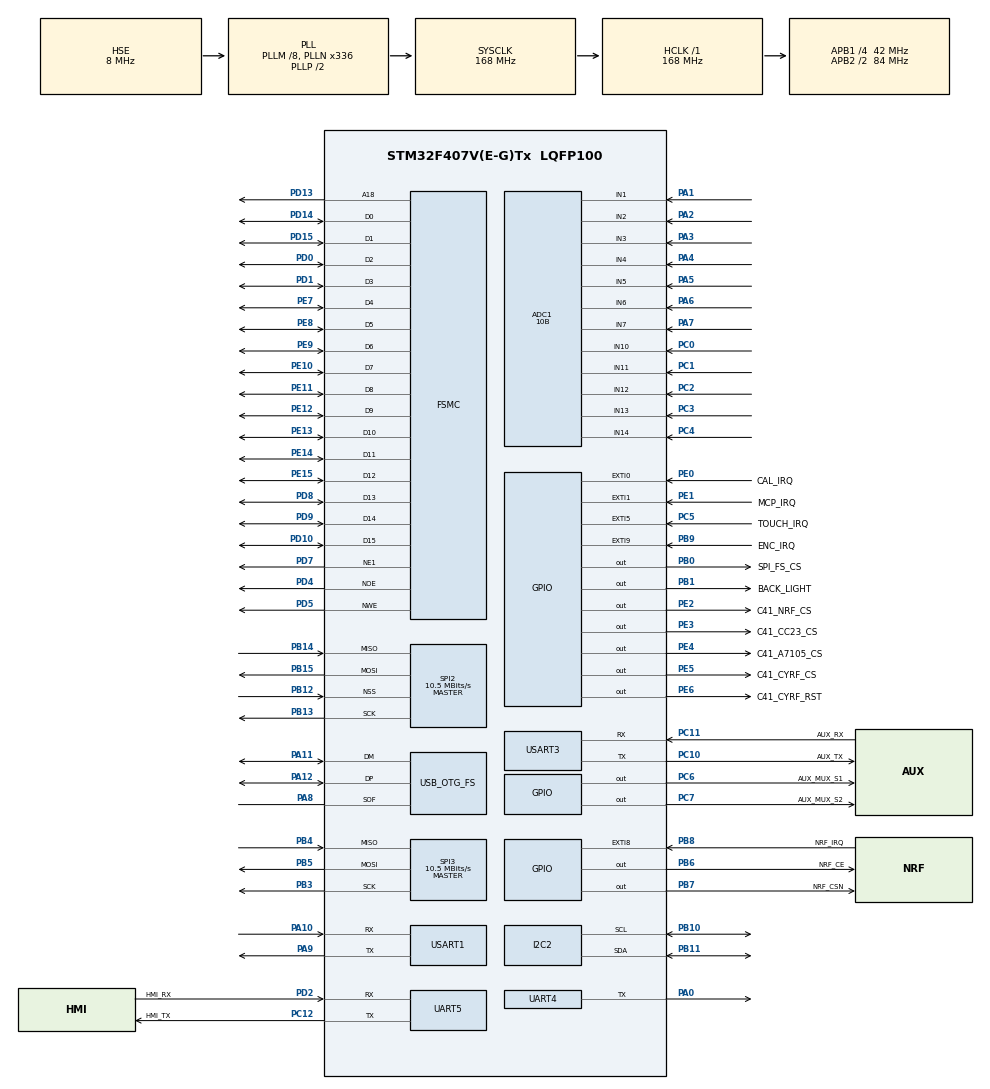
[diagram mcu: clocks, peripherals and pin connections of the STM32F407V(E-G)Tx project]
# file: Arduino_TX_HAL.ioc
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ADC1.Channel-10\#ChannelRegularConversion=ADC_CHANNEL_11
ADC1.Channel-11\#ChannelRegularConversion=ADC_CHANNEL_12
ADC1.Channel-12\#ChannelRegularConversion=ADC_CHANNEL_13
ADC1.Channel-13\#ChannelRegularConversion=ADC_CHANNEL_14
ADC1.Channel-2\#ChannelRegularConversion=ADC_CHANNEL_1
ADC1.Channel-3\#ChannelRegularConversion=ADC_CHANNEL_2
ADC1.Channel-4\#ChannelRegularConversion=ADC_CHANNEL_3
ADC1.Channel-5\#ChannelRegularConversion=ADC_CHANNEL_4
ADC1.Channel-6\#ChannelRegularConversion=ADC_CHANNEL_5
ADC1.Channel-7\#ChannelRegularConversion=ADC_CHANNEL_6
ADC1.Channel-8\#ChannelRegularConversion=ADC_CHANNEL_7
ADC1.Channel-9\#ChannelRegularConversion=ADC_CHANNEL_10
ADC1.ClockPrescaler=ADC_CLOCK_SYNC_PCLK_DIV4
ADC1.ContinuousConvMode=ENABLE
ADC1.DMAContinuousRequests=ENABLE
ADC1.EOCSelection=ADC_EOC_SEQ_CONV
ADC1.NbrOfConversion=12
ADC1.NbrOfConversionFlag=1
ADC1.Rank-10\#ChannelRegularConversion=9
ADC1.Rank-11\#ChannelRegularConversion=10
ADC1.Rank-12\#ChannelRegularConversion=11
ADC1.Rank-13\#ChannelRegularConversion=12
ADC1.Rank-2\#ChannelRegularConversion=1
ADC1.Rank-3\#ChannelRegularConversion=2
ADC1.Rank-4\#ChannelRegularConversion=3
ADC1.Rank-5\#ChannelRegularConversion=4
ADC1.Rank-6\#ChannelRegularConversion=5
ADC1.Rank-7\#ChannelRegularConversion=6
ADC1.Rank-8\#ChannelRegularConversion=7
ADC1.Rank-9\#ChannelRegularConversion=8
ADC1.Resolution=ADC_RESOLUTION_10B
ADC1.SamplingTime-10\#ChannelRegularConversion=ADC_SAMPLETIME_144CYCLES
ADC1.SamplingTime-11\#ChannelRegularConversion=ADC_SAMPLETIME_144CYCLES
ADC1.SamplingTime-12\#ChannelRegularConversion=ADC_SAMPLETIME_144CYCLES
ADC1.SamplingTime-13\#ChannelRegularConversion=ADC_SAMPLETIME_144CYCLES
ADC1.SamplingTime-2\#ChannelRegularConversion=ADC_SAMPLETIME_144CYCLES
ADC1.SamplingTime-3\#ChannelRegularConversion=ADC_SAMPLETIME_144CYCLES
ADC1.SamplingTime-4\#ChannelRegularConversion=ADC_SAMPLETIME_144CYCLES
ADC1.SamplingTime-5\#ChannelRegularConversion=ADC_SAMPLETIME_144CYCLES
ADC1.SamplingTime-6\#ChannelRegularConversion=ADC_SAMPLETIME_144CYCLES
ADC1.SamplingTime-7\#ChannelRegularConversion=ADC_SAMPLETIME_144CYCLES
ADC1.SamplingTime-8\#ChannelRegularConversion=ADC_SAMPLETIME_144CYCLES
ADC1.SamplingTime-9\#ChannelRegularConversion=ADC_SAMPLETIME_144CYCLES
ADC1.ScanConvMode=ENABLE
ADC1.master=1
AL94.I-CUBE-USBD-COMPOSITE.1.0.3.CompositeCcUSBJjCOMPOSITEJjCDCIiACM=true
AL94.I-CUBE-USBD-COMPOSITE.1.0.3.CompositeCcUSBJjCOMPOSITEJjCOMPOSITE=true
AL94.I-CUBE-USBD-COMPOSITE.1.0.3.CompositeCcUSBJjCOMPOSITEJjCore=true
AL94.I-CUBE-USBD-COMPOSITE.1.0.3.CompositeCcUSBJjCOMPOSITEJjDFU=true
AL94.I-CUBE-USBD-COMPOSITE.1.0.3.CompositeCcUSBJjCOMPOSITEJjMSCIiBOT=true
AL94.I-CUBE-USBD-COMPOSITE.1.0.3._USBD_CDC_ACM_COUNT=2
AL94.I-CUBE-USBD-COMPOSITE.1.0.3._USBD_USE_CDC_ACM=true
AL94.I-CUBE-USBD-COMPOSITE.1.0.3._USBD_USE_DFU=true
AL94.I-CUBE-USBD-COMPOSITE.1.0.3._USBD_USE_MSC=true
Dma.ADC1.0.Direction=DMA_PERIPH_TO_MEMORY
Dma.ADC1.0.FIFOMode=DMA_FIFOMODE_DISABLE
Dma.ADC1.0.Instance=DMA2_Stream0
Dma.ADC1.0.MemDataAlignment=DMA_MDATAALIGN_HALFWORD
Dma.ADC1.0.MemInc=DMA_MINC_ENABLE
Dma.ADC1.0.Mode=DMA_CIRCULAR
Dma.ADC1.0.PeriphDataAlignment=DMA_PDATAALIGN_HALFWORD
Dma.ADC1.0.PeriphInc=DMA_PINC_DISABLE
Dma.ADC1.0.Priority=DMA_PRIORITY_LOW
Dma.Request0=ADC1
Dma.Request1=USART1_RX
Dma.Request2=USART1_TX
Dma.Request3=USART3_RX
Dma.Request4=USART3_TX
Dma.Request5=UART5_RX
Dma.Request6=UART5_TX
Dma.Request7=UART4_TX
Dma.UART4_TX.7.Direction=DMA_MEMORY_TO_PERIPH
Dma.UART4_TX.7.FIFOMode=DMA_FIFOMODE_DISABLE
Dma.UART4_TX.7.Instance=DMA1_Stream4
Dma.UART4_TX.7.MemDataAlignment=DMA_MDATAALIGN_BYTE
Dma.UART4_TX.7.MemInc=DMA_MINC_ENABLE
Dma.UART4_TX.7.Mode=DMA_NORMAL
Dma.UART4_TX.7.PeriphDataAlignment=DMA_PDATAALIGN_BYTE
Dma.UART4_TX.7.PeriphInc=DMA_PINC_DISABLE
Dma.UART4_TX.7.Priority=DMA_PRIORITY_LOW
Dma.UART5_RX.5.Direction=DMA_PERIPH_TO_MEMORY
Dma.UART5_RX.5.FIFOMode=DMA_FIFOMODE_DISABLE
Dma.UART5_RX.5.Instance=DMA1_Stream0
Dma.UART5_RX.5.MemDataAlignment=DMA_MDATAALIGN_BYTE
Dma.UART5_RX.5.MemInc=DMA_MINC_ENABLE
Dma.UART5_RX.5.Mode=DMA_NORMAL
Dma.UART5_RX.5.PeriphDataAlignment=DMA_PDATAALIGN_BYTE
Dma.UART5_RX.5.PeriphInc=DMA_PINC_DISABLE
Dma.UART5_RX.5.Priority=DMA_PRIORITY_LOW
Dma.UART5_TX.6.Direction=DMA_MEMORY_TO_PERIPH
Dma.UART5_TX.6.FIFOMode=DMA_FIFOMODE_DISABLE
Dma.UART5_TX.6.Instance=DMA1_Stream7
Dma.UART5_TX.6.MemDataAlignment=DMA_MDATAALIGN_BYTE
Dma.UART5_TX.6.MemInc=DMA_MINC_ENABLE
Dma.UART5_TX.6.Mode=DMA_NORMAL
Dma.UART5_TX.6.PeriphDataAlignment=DMA_PDATAALIGN_BYTE
Dma.UART5_TX.6.PeriphInc=DMA_PINC_DISABLE
Dma.UART5_TX.6.Priority=DMA_PRIORITY_LOW
Dma.USART1_RX.1.Direction=DMA_PERIPH_TO_MEMORY
Dma.USART1_RX.1.FIFOMode=DMA_FIFOMODE_DISABLE
Dma.USART1_RX.1.Instance=DMA2_Stream2
Dma.USART1_RX.1.MemDataAlignment=DMA_MDATAALIGN_BYTE
Dma.USART1_RX.1.MemInc=DMA_MINC_ENABLE
Dma.USART1_RX.1.Mode=DMA_CIRCULAR
Dma.USART1_RX.1.PeriphDataAlignment=DMA_PDATAALIGN_BYTE
Dma.USART1_RX.1.PeriphInc=DMA_PINC_DISABLE
Dma.USART1_RX.1.Priority=DMA_PRIORITY_HIGH
Dma.USART1_TX.2.Direction=DMA_MEMORY_TO_PERIPH
Dma.USART1_TX.2.FIFOMode=DMA_FIFOMODE_DISABLE
Dma.USART1_TX.2.Instance=DMA2_Stream7
Dma.USART1_TX.2.MemDataAlignment=DMA_MDATAALIGN_BYTE
Dma.USART1_TX.2.MemInc=DMA_MINC_ENABLE
Dma.USART1_TX.2.Mode=DMA_NORMAL
Dma.USART1_TX.2.PeriphDataAlignment=DMA_PDATAALIGN_BYTE
Dma.USART1_TX.2.PeriphInc=DMA_PINC_DISABLE
Dma.USART1_TX.2.Priority=DMA_PRIORITY_MEDIUM
Dma.USART3_RX.3.Direction=DMA_PERIPH_TO_MEMORY
Dma.USART3_RX.3.FIFOMode=DMA_FIFOMODE_DISABLE
Dma.USART3_RX.3.Instance=DMA1_Stream1
Dma.USART3_RX.3.MemDataAlignment=DMA_MDATAALIGN_BYTE
Dma.USART3_RX.3.MemInc=DMA_MINC_ENABLE
Dma.USART3_RX.3.Mode=DMA_NORMAL
Dma.USART3_RX.3.PeriphDataAlignment=DMA_PDATAALIGN_BYTE
Dma.USART3_RX.3.PeriphInc=DMA_PINC_DISABLE
Dma.USART3_RX.3.Priority=DMA_PRIORITY_LOW
Dma.USART3_TX.4.Direction=DMA_MEMORY_TO_PERIPH
Dma.USART3_TX.4.FIFOMode=DMA_FIFOMODE_DISABLE
Dma.USART3_TX.4.Instance=DMA1_Stream3
Dma.USART3_TX.4.MemDataAlignment=DMA_MDATAALIGN_BYTE
Dma.USART3_TX.4.MemInc=DMA_MINC_ENABLE
Dma.USART3_TX.4.Mode=DMA_NORMAL
Dma.USART3_TX.4.PeriphDataAlignment=DMA_PDATAALIGN_BYTE
Dma.USART3_TX.4.PeriphInc=DMA_PINC_DISABLE
Dma.USART3_TX.4.Priority=DMA_PRIORITY_LOW
I2C2.I2C_Mode=I2C_Fast
Mcu.Family=STM32F4
Mcu.Name=STM32F407V(E-G)Tx
Mcu.Package=LQFP100
NVIC.ADC_IRQn=true\:5\:0\:true\:false\:true\:true\:true\:true
NVIC.DMA1_Stream0_IRQn=true\:7\:0\:true\:false\:true\:false\:true\:true
NVIC.DMA1_Stream1_IRQn=true\:7\:0\:true\:false\:true\:false\:true\:true
NVIC.DMA1_Stream3_IRQn=true\:7\:0\:true\:false\:true\:false\:true\:true
NVIC.DMA1_Stream4_IRQn=true\:7\:0\:true\:false\:true\:false\:true\:true
NVIC.DMA1_Stream7_IRQn=true\:7\:0\:true\:false\:true\:false\:true\:true
NVIC.DMA2_Stream0_IRQn=true\:7\:0\:true\:false\:true\:false\:true\:true
NVIC.DMA2_Stream2_IRQn=true\:7\:0\:true\:false\:true\:false\:true\:true
NVIC.DMA2_Stream7_IRQn=true\:5\:0\:true\:false\:true\:false\:true\:true
NVIC.EXTI0_IRQn=true\:5\:0\:true\:false\:true\:true\:true\:true
NVIC.EXTI1_IRQn=true\:5\:0\:true\:false\:true\:true\:true\:true
NVIC.EXTI9_5_IRQn=true\:5\:0\:true\:false\:true\:true\:true\:true
NVIC.OTG_FS_IRQn=true\:5\:0\:true\:false\:true\:true\:true\:true
NVIC.PriorityGroup=NVIC_PRIORITYGROUP_4
NVIC.TIM8_TRG_COM_TIM14_IRQn=true\:5\:0\:true\:false\:true\:false\:true\:true
NVIC.TimeBase=TIM8_TRG_COM_TIM14_IRQn
NVIC.TimeBaseIP=TIM14
NVIC.UART4_IRQn=true\:0\:0\:false\:false\:true\:true\:true\:true
NVIC.UART5_IRQn=true\:5\:0\:true\:false\:true\:true\:true\:true
NVIC.USART1_IRQn=true\:5\:0\:true\:false\:true\:true\:true\:true
NVIC.USART3_IRQn=true\:5\:0\:true\:false\:true\:true\:true\:true
PA0-WKUP.Mode=Half_duplex(single_wire_mode)
PA0-WKUP.Signal=UART4_TX
PA1.Signal=ADCx_IN1
PA10.Mode=Asynchronous
PA10.Signal=USART1_RX
PA11.Mode=Device_Only
PA11.Signal=USB_OTG_FS_DM
PA12.Mode=Device_Only
PA12.Signal=USB_OTG_FS_DP
PA13.Mode=Serial_Wire
PA13.Signal=SYS_JTMS-SWDIO
PA14.Mode=Serial_Wire
PA14.Signal=SYS_JTCK-SWCLK
PA2.Signal=ADCx_IN2
PA3.Signal=ADCx_IN3
PA4.Signal=ADCx_IN4
PA5.Signal=ADCx_IN5
PA6.Signal=ADCx_IN6
PA7.Signal=ADCx_IN7
PA8.Mode=Activate_SOF_FS
PA8.Signal=USB_OTG_FS_SOF
PA9.Mode=Asynchronous
PA9.Signal=USART1_TX
PB0.GPIO_Label=SPI_FS_CS
PB0.PinState=GPIO_PIN_SET
PB0.Signal=GPIO_Output
PB1.GPIO_Label=BACK_LIGHT
PB1.Signal=GPIO_Output
PB10.Mode=I2C
PB10.Signal=I2C2_SCL
PB11.Mode=I2C
PB11.Signal=I2C2_SDA
PB12.Mode=NSS_Signal_Hard_Input
PB12.Signal=SPI2_NSS
PB13.Mode=Full_Duplex_Master
PB13.Signal=SPI2_SCK
PB14.Mode=Full_Duplex_Master
PB14.Signal=SPI2_MISO
PB15.Mode=Full_Duplex_Master
PB15.Signal=SPI2_MOSI
PB3.Mode=Full_Duplex_Master
PB3.Signal=SPI3_SCK
PB4.Mode=Full_Duplex_Master
PB4.Signal=SPI3_MISO
PB5.Mode=Full_Duplex_Master
PB5.Signal=SPI3_MOSI
PB6.GPIO_Label=NRF_CE
PB6.GPIO_Speed=GPIO_SPEED_FREQ_VERY_HIGH
PB6.Signal=GPIO_Output
PB7.GPIO_Label=NRF_CSN
PB7.GPIO_Speed=GPIO_SPEED_FREQ_VERY_HIGH
PB7.PinState=GPIO_PIN_SET
PB7.Signal=GPIO_Output
PB8.GPIO_Label=NRF_IRQ
PB8.Signal=GPXTI8
PB9.GPIO_Label=ENC_IRQ
PB9.GPIO_ModeDefaultEXTI=GPIO_MODE_IT_FALLING
PB9.GPIO_PuPd=GPIO_PULLUP
PB9.Signal=GPXTI9
PC0.Signal=ADCx_IN10
PC1.Signal=ADCx_IN11
PC10.GPIO_Label=AUX_TX
PC10.Mode=Asynchronous
PC10.Signal=USART3_TX
PC11.GPIO_Label=AUX_RX
PC11.Mode=Asynchronous
PC11.Signal=USART3_RX
PC12.GPIO_Label=HMI_TX
PC12.Mode=Asynchronous
PC12.Signal=UART5_TX
PC14-OSC32_IN.Mode=LSE-External-Oscillator
PC14-OSC32_IN.Signal=RCC_OSC32_IN
PC15-OSC32_OUT.Mode=LSE-External-Oscillator
PC15-OSC32_OUT.Signal=RCC_OSC32_OUT
PC2.Signal=ADCx_IN12
PC3.Signal=ADCx_IN13
PC4.Signal=ADCx_IN14
PC5.GPIO_Label=TOUCH_IRQ
PC5.GPIO_ModeDefaultEXTI=GPIO_MODE_IT_FALLING
PC5.GPIO_PuPd=GPIO_PULLUP
PC5.Signal=GPXTI5
PC6.GPIO_Label=AUX_MUX_S1
PC6.Signal=GPIO_Output
PC7.GPIO_Label=AUX_MUX_S2
PC7.Signal=GPIO_Output
PD0.Mode=16b-d1
PD0.Signal=FSMC_D2
PD1.Mode=16b-d1
PD1.Signal=FSMC_D3
PD10.Mode=16b-d1
PD10.Signal=FSMC_D15
PD13.Mode=A18_1
PD13.Signal=FSMC_A18
PD14.Mode=16b-d1
PD14.Signal=FSMC_D0
PD15.Mode=16b-d1
PD15.Signal=FSMC_D1
PD2.GPIO_Label=HMI_RX
PD2.Mode=Asynchronous
PD2.Signal=UART5_RX
PD4.Mode=Lcd1
PD4.Signal=FSMC_NOE
PD5.Mode=Lcd1
PD5.Signal=FSMC_NWE
PD7.Mode=NorPsramChipSelect1_1
PD7.Signal=FSMC_NE1
PD8.Mode=16b-d1
PD8.Signal=FSMC_D13
PD9.Mode=16b-d1
PD9.Signal=FSMC_D14
PE0.GPIO_Label=CAL_IRQ
PE0.GPIO_ModeDefaultEXTI=GPIO_MODE_IT_FALLING
PE0.GPIO_PuPd=GPIO_PULLUP
PE0.Signal=GPXTI0
PE1.GPIO_Label=MCP_IRQ
PE1.GPIO_ModeDefaultEXTI=GPIO_MODE_IT_FALLING
PE1.GPIO_PuPd=GPIO_PULLUP
PE1.Signal=GPXTI1
PE10.Mode=16b-d1
PE10.Signal=FSMC_D7
PE11.Mode=16b-d1
PE11.Signal=FSMC_D8
PE12.Mode=16b-d1
PE12.Signal=FSMC_D9
PE13.Mode=16b-d1
PE13.Signal=FSMC_D10
PE14.Mode=16b-d1
PE14.Signal=FSMC_D11
PE15.Mode=16b-d1
PE15.Signal=FSMC_D12
PE2.GPIO_Label=C41_NRF_CS
PE2.Signal=GPIO_Output
PE3.GPIO_Label=C41_CC23_CS
PE3.Signal=GPIO_Output
PE4.GPIO_Label=C41_A7105_CS
PE4.Signal=GPIO_Output
PE5.GPIO_Label=C41_CYRF_CS
PE5.Signal=GPIO_Output
PE6.GPIO_Label=C41_CYRF_RST
PE6.Signal=GPIO_Output
PE7.Mode=16b-d1
PE7.Signal=FSMC_D4
PE8.Mode=16b-d1
PE8.Signal=FSMC_D5
PE9.Mode=16b-d1
PE9.Signal=FSMC_D6
PH0-OSC_IN.Mode=HSE-External-Oscillator
PH0-OSC_IN.Signal=RCC_OSC_IN
PH1-OSC_OUT.Mode=HSE-External-Oscillator
PH1-OSC_OUT.Signal=RCC_OSC_OUT
ProjectManager.HeapSize=0x200
ProjectManager.StackSize=0x400
ProjectManager.TargetToolchain=STM32CubeIDE
RCC.48MHZClocksFreq_Value=48000000
RCC.AHBFreq_Value=168000000
RCC.APB1CLKDivider=RCC_HCLK_DIV4
RCC.APB1Freq_Value=42000000
RCC.APB1TimFreq_Value=84000000
RCC.APB2CLKDivider=RCC_HCLK_DIV2
RCC.APB2Freq_Value=84000000
RCC.APB2TimFreq_Value=168000000
RCC.CortexFreq_Value=168000000
RCC.HCLKFreq_Value=168000000
RCC.HSE_VALUE=8000000
RCC.HSI_VALUE=16000000
RCC.PLLM=8
RCC.PLLN=336
RCC.PLLQ=7
RCC.SYSCLKFreq_VALUE=168000000
RCC.SYSCLKSource=RCC_SYSCLKSOURCE_PLLCLK
RCC.VCOOutputFreq_Value=336000000
SH.ADCx_IN1.0=ADC1_IN1,IN1
SH.ADCx_IN10.0=ADC1_IN10,IN10
SH.ADCx_IN11.0=ADC1_IN11,IN11
SH.ADCx_IN12.0=ADC1_IN12,IN12
SH.ADCx_IN13.0=ADC1_IN13,IN13
SH.ADCx_IN14.0=ADC1_IN14,IN14
SH.ADCx_IN2.0=ADC1_IN2,IN2
SH.ADCx_IN3.0=ADC1_IN3,IN3
SH.ADCx_IN4.0=ADC1_IN4,IN4
SH.ADCx_IN5.0=ADC1_IN5,IN5
SH.ADCx_IN6.0=ADC1_IN6,IN6
SH.ADCx_IN7.0=ADC1_IN7,IN7
SPI2.BaudRatePrescaler=SPI_BAUDRATEPRESCALER_4
SPI2.CalculateBaudRate=10.5 MBits/s
SPI2.Direction=SPI_DIRECTION_2LINES
SPI2.Mode=SPI_MODE_MASTER
SPI2.VirtualNSS=VM_NSSHARD
SPI2.VirtualType=VM_MASTER
SPI3.BaudRatePrescaler=SPI_BAUDRATEPRESCALER_4
SPI3.CalculateBaudRate=10.5 MBits/s
SPI3.Direction=SPI_DIRECTION_2LINES
SPI3.Mode=SPI_MODE_MASTER
SPI3.VirtualType=VM_MASTER
STMicroelectronics.X-CUBE-TOUCHGFX.4.25.0.tgfx_buffering_strategy=Single
STMicroelectronics.X-CUBE-TOUCHGFX.4.25.0.tgfx_custom_height=320
STMicroelectronics.X-CUBE-TOUCHGFX.4.25.0.tgfx_custom_width=480
STMicroelectronics.X-CUBE-TOUCHGFX.4.25.0.tgfx_datareader=Disabled
STMicroelectronics.X-CUBE-TOUCHGFX.4.25.0.tgfx_display_interface=disp_fmc
STMicroelectronics.X-CUBE-TOUCHGFX.4.25.0.tgfx_location=Allocate
STMicroelectronics.X-CUBE-TOUCHGFX.4.25.0.tgfx_vector_rendering=Disabled
STMicroelectronics.X-CUBE-TOUCHGFX.4.25.0_IsPackSelfContextualization=true
TIM13.Prescaler=83
UART4.Mode=MODE_TX
UART4.VirtualMode=Asynchronous
UART5.VirtualMode=Asynchronous
USART1.VirtualMode=VM_ASYNC
USART3.VirtualMode=VM_ASYNC
USB_OTG_FS.VirtualMode=Device_Only
USB_OTG_FS.lpm_enable=DISABLE
VP_AL94.I-CUBE-USBD-COMPOSITE_VS_USBJjComposite_1.0.0_1.0.3.Mode=USBJjComposite
VP_CRC_VS_CRC.Mode=CRC_Activate
VP_SYS_VS_tim14.Mode=TIM14
VP_TIM13_VS_ClockSourceINT.Mode=Enable_Timer
board=custom

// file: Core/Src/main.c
/* USER CODE BEGIN Header */
/**
 ******************************************************************************
 * @file           : main.c
 * @brief          : Main program body
 ******************************************************************************
 * @attention
 *
 * Copyright (c) 2025 STMicroelectronics.
 * All rights reserved.
 *
 * This software is licensed under terms that can be found in the LICENSE file
 * in the root directory of this software component.
 * If no LICENSE file comes with this software, it is provided AS-IS.
 *
 ******************************************************************************
 */
/* USER CODE END Header */
#include "main.h"
#include "adc.h"
#include "crc.h"
#include "dma.h"
#include "i2c.h"
#include "spi.h"
#include "tim.h"
#include "usart.h"
#include "usb_otg.h"
#include "gpio.h"
#include "fsmc.h"

/* USER CODE BEGIN Includes */
#include "Config.h"
#include "usb_device.h"
#include <stdio.h>

#include "Arduino_TX_HAL.h"
/* USER CODE END Includes */

void SystemClock_Config(void);

/* USER CODE BEGIN 0 */

void HAL_Delay(uint32_t Delay) {
    TaskHandle_t currentTask = xTaskGetCurrentTaskHandle();
    BaseType_t taskSchedulerState = xTaskGetSchedulerState();
    if (currentTask == NULL || taskSchedulerState != taskSCHEDULER_RUNNING) {
        uint32_t tickstart = HAL_GetTick();
        uint32_t wait = Delay;

        /* Add a freq to guarantee minimum wait */
        if (wait < HAL_MAX_DELAY) {
            wait += (uint32_t)(uwTickFreq);
        }
        uint32_t currentTick = HAL_GetTick();
        while ((currentTick - tickstart) < wait) {
            currentTick = HAL_GetTick();
        }
    } else {
        vTaskDelay(Delay / portTICK_PERIOD_MS);
    }
}

void delay_us(uint16_t us) {
    __HAL_TIM_SET_COUNTER(&htim13, 0); // set the counter value a 0
    while (__HAL_TIM_GET_COUNTER(&htim13) < us)
        ;                              // wait for the counter to reach the us input in the parameter
}

/* USER CODE END 0 */

int main(void)
{

  /* USER CODE BEGIN 1 */
    CoreDebug->DEMCR |= CoreDebug_DEMCR_VC_HARDERR_Msk; // Enable direct breakpoint on hardfault
  /* USER CODE END 1 */

  /* MCU Configuration--------------------------------------------------------*/

  /* Reset of all peripherals, Initializes the Flash interface and the Systick. */
  HAL_Init();

  /* Configure the system clock */
  SystemClock_Config();

  /* Initialize all configured peripherals */
  MX_GPIO_Init();
  MX_DMA_Init();
  MX_ADC1_Init();
  MX_FSMC_Init();
  MX_I2C2_Init();
  MX_SPI2_Init();
  MX_UART5_Init();
  MX_USART1_UART_Init();
  MX_USART3_UART_Init();
  MX_CRC_Init();
  MX_USB_OTG_FS_PCD_Init();
  MX_SPI3_Init();
  MX_TIM13_Init();
  MX_UART4_Init();
  /* USER CODE BEGIN 2 */
#if ENABLE_USB
    MX_USB_DEVICE_Init();
#endif

    NVIC_SetPriorityGrouping(NVIC_PRIORITYGROUP_4);
    setupCPP();
    startFreeRTOS();
  /* USER CODE END 2 */

  /* Infinite loop */
  /* USER CODE BEGIN WHILE */
    // Useless loop, we should not get into this one
    while (1) {
    /* USER CODE END WHILE */

    }
}

void SystemClock_Config(void)
{
  RCC_OscInitTypeDef RCC_OscInitStruct = {0};
  RCC_ClkInitTypeDef RCC_ClkInitStruct = {0};

  /** Configure the main internal regulator output voltage
  */
  __HAL_RCC_PWR_CLK_ENABLE();
  __HAL_PWR_VOLTAGESCALING_CONFIG(PWR_REGULATOR_VOLTAGE_SCALE1);

  /** Initializes the RCC Oscillators according to the specified parameters
  * in the RCC_OscInitTypeDef structure.
  */
  RCC_OscInitStruct.OscillatorType = RCC_OSCILLATORTYPE_HSE;
  RCC_OscInitStruct.HSEState = RCC_HSE_ON;
  RCC_OscInitStruct.PLL.PLLState = RCC_PLL_ON;
  RCC_OscInitStruct.PLL.PLLSource = RCC_PLLSOURCE_HSE;
  RCC_OscInitStruct.PLL.PLLM = 8;
  RCC_OscInitStruct.PLL.PLLN = 336;
  RCC_OscInitStruct.PLL.PLLP = RCC_PLLP_DIV2;
  RCC_OscInitStruct.PLL.PLLQ = 7;
  if (HAL_RCC_OscConfig(&RCC_OscInitStruct) != HAL_OK)
  {
    Error_Handler();
  }

  /** Initializes the CPU, AHB and APB buses clocks
  */
  RCC_ClkInitStruct.ClockType = RCC_CLOCKTYPE_HCLK|RCC_CLOCKTYPE_SYSCLK
                              |RCC_CLOCKTYPE_PCLK1|RCC_CLOCKTYPE_PCLK2;
  RCC_ClkInitStruct.SYSCLKSource = RCC_SYSCLKSOURCE_PLLCLK;
  RCC_ClkInitStruct.AHBCLKDivider = RCC_SYSCLK_DIV1;
  RCC_ClkInitStruct.APB1CLKDivider = RCC_HCLK_DIV4;
  RCC_ClkInitStruct.APB2CLKDivider = RCC_HCLK_DIV2;

  if (HAL_RCC_ClockConfig(&RCC_ClkInitStruct, FLASH_LATENCY_5) != HAL_OK)
  {
    Error_Handler();
  }
}

void HAL_TIM_PeriodElapsedCallback(TIM_HandleTypeDef *htim)
{
  if (htim->Instance == TIM14)
  {
    HAL_IncTick();
  }
}

void Error_Handler(void)
{
  /* USER CODE BEGIN Error_Handler_Debug */
    /* User can add his own implementation to report the HAL error return state */
    Error_Handler_CPP(file, line);
  /* USER CODE END Error_Handler_Debug */
}
